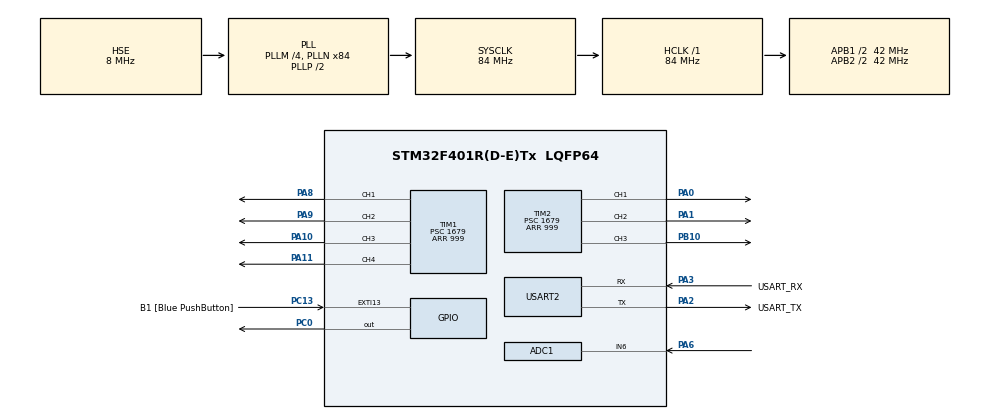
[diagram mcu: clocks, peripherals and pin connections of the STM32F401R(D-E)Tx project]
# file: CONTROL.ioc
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ADC1.Channel-0\#ChannelRegularConversion=ADC_CHANNEL_6
ADC1.NbrOfConversionFlag=1
ADC1.Rank-0\#ChannelRegularConversion=1
ADC1.SamplingTime-0\#ChannelRegularConversion=ADC_SAMPLETIME_3CYCLES
ADC1.master=1
Mcu.Family=STM32F4
Mcu.Name=STM32F401R(D-E)Tx
Mcu.Package=LQFP64
NVIC.PriorityGroup=NVIC_PRIORITYGROUP_0
NVIC.TIM1_BRK_TIM9_IRQn=true\:0\:0\:false\:false\:true\:true
NVIC.TIM1_CC_IRQn=true\:0\:0\:false\:false\:true\:true
NVIC.TIM1_TRG_COM_TIM11_IRQn=true\:0\:0\:false\:false\:true\:true
NVIC.TIM1_UP_TIM10_IRQn=true\:0\:0\:false\:false\:true\:true
NVIC.TIM2_IRQn=true\:0\:0\:false\:false\:true\:true
NVIC.TIM3_IRQn=true\:0\:0\:false\:false\:true\:true
PA0-WKUP.GPIO_Speed=GPIO_SPEED_FREQ_HIGH
PA0-WKUP.Signal=S_TIM2_CH1_ETR
PA1.Signal=S_TIM2_CH2
PA10.GPIO_Speed=GPIO_SPEED_FREQ_VERY_HIGH
PA10.Signal=S_TIM1_CH3
PA11.GPIO_Speed=GPIO_SPEED_FREQ_VERY_HIGH
PA11.Signal=S_TIM1_CH4
PA13.GPIO_Label=TMS
PA13.Mode=Serial_Wire
PA13.Signal=SYS_JTMS-SWDIO
PA14.GPIO_Label=TCK
PA14.Mode=Serial_Wire
PA14.Signal=SYS_JTCK-SWCLK
PA2.GPIO_Label=USART_TX
PA2.GPIO_Mode=GPIO_MODE_AF_PP
PA2.GPIO_PuPd=GPIO_NOPULL
PA2.GPIO_Speed=GPIO_SPEED_FREQ_LOW
PA2.Mode=Asynchronous
PA2.Signal=USART2_TX
PA3.GPIO_Label=USART_RX
PA3.GPIO_Mode=GPIO_MODE_AF_PP
PA3.GPIO_PuPd=GPIO_NOPULL
PA3.GPIO_Speed=GPIO_SPEED_FREQ_LOW
PA3.Mode=Asynchronous
PA3.Signal=USART2_RX
PA6.Signal=ADCx_IN6
PA8.GPIO_Speed=GPIO_SPEED_FREQ_VERY_HIGH
PA8.Signal=S_TIM1_CH1
PA9.GPIO_Speed=GPIO_SPEED_FREQ_VERY_HIGH
PA9.Signal=S_TIM1_CH2
PB10.Signal=S_TIM2_CH3
PB3.GPIO_Label=SWO
PB3.Signal=SYS_JTDO-SWO
PC0.Signal=GPIO_Output
PC13-ANTI_TAMP.GPIO_Label=B1 [Blue PushButton]
PC13-ANTI_TAMP.GPIO_ModeDefaultEXTI=GPIO_MODE_IT_FALLING
PC13-ANTI_TAMP.GPIO_PuPd=GPIO_NOPULL
PC13-ANTI_TAMP.Signal=GPXTI13
PC14-OSC32_IN.Mode=LSE-External-Oscillator
PC14-OSC32_IN.Signal=RCC_OSC32_IN
PC15-OSC32_OUT.Mode=LSE-External-Oscillator
PC15-OSC32_OUT.Signal=RCC_OSC32_OUT
PH0\ -\ OSC_IN.Mode=HSE-External-Clock-Source
PH0\ -\ OSC_IN.Signal=RCC_OSC_IN
PH1\ -\ OSC_OUT.Mode=HSE-External-Clock-Source
PH1\ -\ OSC_OUT.Signal=RCC_OSC_OUT
ProjectManager.HeapSize=0x200
ProjectManager.StackSize=0x400
ProjectManager.TargetToolchain=MDK-ARM V5
RCC.48MHZClocksFreq_Value=24000000
RCC.AHBFreq_Value=84000000
RCC.APB1CLKDivider=RCC_HCLK_DIV2
RCC.APB1Freq_Value=42000000
RCC.APB1TimFreq_Value=84000000
RCC.APB2CLKDivider=RCC_HCLK_DIV2
RCC.APB2Freq_Value=42000000
RCC.APB2TimFreq_Value=84000000
RCC.CortexFreq_Value=84000000
RCC.HCLKFreq_Value=84000000
RCC.HSE_VALUE=8000000
RCC.HSI_VALUE=16000000
RCC.PLLM=8
RCC.PLLN=84
RCC.PLLQ=7
RCC.SYSCLKFreq_VALUE=84000000
RCC.SYSCLKSource=RCC_SYSCLKSOURCE_PLLCLK
RCC.VCOOutputFreq_Value=168000000
SH.ADCx_IN6.0=ADC1_IN6,IN6
SH.S_TIM1_CH1.0=TIM1_CH1,PWM Generation1 CH1
SH.S_TIM1_CH2.0=TIM1_CH2,PWM Generation2 CH2
SH.S_TIM1_CH3.0=TIM1_CH3,PWM Generation3 CH3
SH.S_TIM1_CH4.0=TIM1_CH4,PWM Generation4 CH4
SH.S_TIM2_CH1_ETR.0=TIM2_CH1,PWM Generation1 CH1
SH.S_TIM2_CH2.0=TIM2_CH2,PWM Generation2 CH2
SH.S_TIM2_CH3.0=TIM2_CH3,PWM Generation3 CH3
TIM1.Channel-PWM\ Generation1\ CH1=TIM_CHANNEL_1
TIM1.Channel-PWM\ Generation2\ CH2=TIM_CHANNEL_2
TIM1.Channel-PWM\ Generation3\ CH3=TIM_CHANNEL_3
TIM1.Channel-PWM\ Generation4\ CH4=TIM_CHANNEL_4
TIM1.Period=999
TIM1.Prescaler=1679
TIM2.Channel-PWM\ Generation1\ CH1=TIM_CHANNEL_1
TIM2.Channel-PWM\ Generation2\ CH2=TIM_CHANNEL_2
TIM2.Channel-PWM\ Generation3\ CH3=TIM_CHANNEL_3
TIM2.Period=999
TIM2.Prescaler=1679
TIM3.Period=999
TIM3.Prescaler=8399
USART2.VirtualMode=VM_ASYNC
VP_TIM1_VS_ClockSourceINT.Mode=Internal
VP_TIM2_VS_ClockSourceINT.Mode=Internal
VP_TIM3_VS_ClockSourceINT.Mode=Internal
VP_TIM3_VS_OPM.Mode=OPM_bit
board=NUCLEO-F401RE

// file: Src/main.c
/* USER CODE BEGIN Header */
/**
  ******************************************************************************
  * @file           : main.c
  * @brief          : Main program body
  ******************************************************************************
  ** This notice applies to any and all portions of this file
  * that are not between comment pairs USER CODE BEGIN and
  * USER CODE END. Other portions of this file, whether
  * inserted by the user or by software development tools
  * are owned by their respective copyright owners.
  *
  * COPYRIGHT(c) 2018 STMicroelectronics
  *
  * Redistribution and use in source and binary forms, with or without modification,
  * are permitted provided that the following conditions are met:
  *   1. Redistributions of source code must retain the above copyright notice,
  *      this list of conditions and the following disclaimer.
  *   2. Redistributions in binary form must reproduce the above copyright notice,
  *      this list of conditions and the following disclaimer in the documentation
  *      and/or other materials provided with the distribution.
  *   3. Neither the name of STMicroelectronics nor the names of its contributors
  *      may be used to endorse or promote products derived from this software
  *      without specific prior written permission.
  *
  * THIS SOFTWARE IS PROVIDED BY THE COPYRIGHT HOLDERS AND CONTRIBUTORS "AS IS"
  * AND ANY EXPRESS OR IMPLIED WARRANTIES, INCLUDING, BUT NOT LIMITED TO, THE
  * IMPLIED WARRANTIES OF MERCHANTABILITY AND FITNESS FOR A PARTICULAR PURPOSE ARE
  * DISCLAIMED. IN NO EVENT SHALL THE COPYRIGHT HOLDER OR CONTRIBUTORS BE LIABLE
  * FOR ANY DIRECT, INDIRECT, INCIDENTAL, SPECIAL, EXEMPLARY, OR CONSEQUENTIAL
  * DAMAGES (INCLUDING, BUT NOT LIMITED TO, PROCUREMENT OF SUBSTITUTE GOODS OR
  * SERVICES; LOSS OF USE, DATA, OR PROFITS; OR BUSINESS INTERRUPTION) HOWEVER
  * CAUSED AND ON ANY THEORY OF LIABILITY, WHETHER IN CONTRACT, STRICT LIABILITY,
  * OR TORT (INCLUDING NEGLIGENCE OR OTHERWISE) ARISING IN ANY WAY OUT OF THE USE
  * OF THIS SOFTWARE, EVEN IF ADVISED OF THE POSSIBILITY OF SUCH DAMAGE.
  *
  ******************************************************************************
  */
/* USER CODE END Header */

#include "main.h"

/* USER CODE BEGIN Includes */
#include "servo.h"
#include "motorController.h"
#include <stdlib.h>
//#include "motorController.h"

/* USER CODE END Includes */

ADC_HandleTypeDef hadc1;

TIM_HandleTypeDef htim1;
TIM_HandleTypeDef htim2;
TIM_HandleTypeDef htim3;

UART_HandleTypeDef huart2;

void SystemClock_Config(void);
static void MX_GPIO_Init(void);
static void MX_USART2_UART_Init(void);
static void MX_TIM2_Init(void);
static void MX_ADC1_Init(void);
static void MX_TIM1_Init(void);
static void MX_TIM3_Init(void);

int main(void)
{

  /* MCU Configuration--------------------------------------------------------*/

  /* Reset of all peripherals, Initializes the Flash interface and the Systick. */
  HAL_Init();

  /* Configure the system clock */
  SystemClock_Config();

  /* Initialize all configured peripherals */
  MX_GPIO_Init();
  MX_USART2_UART_Init();
  MX_TIM2_Init();
  MX_ADC1_Init();
  MX_TIM1_Init();
  MX_TIM3_Init();
  /* USER CODE BEGIN 2 */

	// init pwm for servo
	HAL_TIM_PWM_Start( &htim2,TIM_CHANNEL_1 );
	// init pwm for thrasters on timer 1
	HAL_TIM_PWM_Start( &htim1,TIM_CHANNEL_1 );
	HAL_TIM_PWM_Start( &htim1,TIM_CHANNEL_2 );
	HAL_TIM_PWM_Start( &htim1,TIM_CHANNEL_3 );
	HAL_TIM_PWM_Start( &htim1,TIM_CHANNEL_4 );
	// init pwm for thrusters on timer 2
	HAL_TIM_PWM_Start( &htim2,TIM_CHANNEL_2 );
	HAL_TIM_PWM_Start( &htim2,TIM_CHANNEL_3 );

	MotorsInit( &htim1, &htim2 ); // init brushles motors

  /* USER CODE END 2 */

  /* Infinite loop */
  /* USER CODE BEGIN WHILE */
	char Data[32];
  while (1)
  {

				HAL_ADC_Start( &hadc1 );
				HAL_ADC_PollForConversion( &hadc1,100 );
				int power=GetServoAngle( &hadc1 ); //read value from resistor
				power -= 63;
				HAL_ADC_Stop( &hadc1 );
				int size = sprintf((char *)Data,"\r\n%d",power);
				HAL_UART_Transmit(&huart2, Data, size, 1000);

				/*if(__HAL_UART_GET_FLAG(&huart2, UART_FLAG_RXNE))
			{
				HAL_UART_Receive( &huart2, dataAngle,  sizeof(dataAngle), 1000 );

				HAL_UART_Transmit( &huart2, dataAngle, sizeof(dataAngle), 1000 );
				//angle1=SetServoAngle( atoi((char*)dataAngle) ,&hadc1,&htim2 );
				int flag=atoi((char*)dataAngle);

				if(flag==1)
				{
					HAL_GPIO_WritePin(GPIOC, GPIO_PIN_0, GPIO_PIN_SET);
					HAL_Delay(200);
					HAL_GPIO_WritePin(GPIOC, GPIO_PIN_0, GPIO_PIN_RESET);
				}

			}*/

			SetMotorThrust( power,&htim2,2 );
			SetMotorThrust( power,&htim2,3 );

			SetMotorThrust( power,&htim1,1 );
			SetMotorThrust( power,&htim1,2 );
			SetMotorThrust( power,&htim1,3 );
			SetMotorThrust( power,&htim1,4 );

			HAL_Delay( 200 );

    /* USER CODE END WHILE */

  }
}

void SystemClock_Config(void)
{
  RCC_OscInitTypeDef RCC_OscInitStruct = {0};
  RCC_ClkInitTypeDef RCC_ClkInitStruct = {0};

  /**Configure the main internal regulator output voltage
  */
  __HAL_RCC_PWR_CLK_ENABLE();
  __HAL_PWR_VOLTAGESCALING_CONFIG(PWR_REGULATOR_VOLTAGE_SCALE2);
  /**Initializes the CPU, AHB and APB busses clocks
  */
  RCC_OscInitStruct.OscillatorType = RCC_OSCILLATORTYPE_HSE;
  RCC_OscInitStruct.HSEState = RCC_HSE_BYPASS;
  RCC_OscInitStruct.PLL.PLLState = RCC_PLL_ON;
  RCC_OscInitStruct.PLL.PLLSource = RCC_PLLSOURCE_HSE;
  RCC_OscInitStruct.PLL.PLLM = 4;
  RCC_OscInitStruct.PLL.PLLN = 84;
  RCC_OscInitStruct.PLL.PLLP = RCC_PLLP_DIV2;
  RCC_OscInitStruct.PLL.PLLQ = 7;
  if (HAL_RCC_OscConfig(&RCC_OscInitStruct) != HAL_OK)
  {
    Error_Handler();
  }
  /**Initializes the CPU, AHB and APB busses clocks
  */
  RCC_ClkInitStruct.ClockType = RCC_CLOCKTYPE_HCLK|RCC_CLOCKTYPE_SYSCLK
                              |RCC_CLOCKTYPE_PCLK1|RCC_CLOCKTYPE_PCLK2;
  RCC_ClkInitStruct.SYSCLKSource = RCC_SYSCLKSOURCE_PLLCLK;
  RCC_ClkInitStruct.AHBCLKDivider = RCC_SYSCLK_DIV1;
  RCC_ClkInitStruct.APB1CLKDivider = RCC_HCLK_DIV2;
  RCC_ClkInitStruct.APB2CLKDivider = RCC_HCLK_DIV2;

  if (HAL_RCC_ClockConfig(&RCC_ClkInitStruct, FLASH_LATENCY_2) != HAL_OK)
  {
    Error_Handler();
  }
}

static void MX_ADC1_Init(void)
{

  ADC_ChannelConfTypeDef sConfig = {0};

  /**Configure the global features of the ADC (Clock, Resolution, Data Alignment and number of conversion)
  */
  hadc1.Instance = ADC1;
  hadc1.Init.ClockPrescaler = ADC_CLOCK_SYNC_PCLK_DIV2;
  hadc1.Init.Resolution = ADC_RESOLUTION_12B;
  hadc1.Init.ScanConvMode = DISABLE;
  hadc1.Init.ContinuousConvMode = DISABLE;
  hadc1.Init.DiscontinuousConvMode = DISABLE;
  hadc1.Init.ExternalTrigConvEdge = ADC_EXTERNALTRIGCONVEDGE_NONE;
  hadc1.Init.ExternalTrigConv = ADC_SOFTWARE_START;
  hadc1.Init.DataAlign = ADC_DATAALIGN_RIGHT;
  hadc1.Init.NbrOfConversion = 1;
  hadc1.Init.DMAContinuousRequests = DISABLE;
  hadc1.Init.EOCSelection = ADC_EOC_SINGLE_CONV;
  if (HAL_ADC_Init(&hadc1) != HAL_OK)
  {
    Error_Handler();
  }
  /**Configure for the selected ADC regular channel its corresponding rank in the sequencer and its sample time.
  */
  sConfig.Channel = ADC_CHANNEL_6;
  sConfig.Rank = 1;
  sConfig.SamplingTime = ADC_SAMPLETIME_3CYCLES;
  if (HAL_ADC_ConfigChannel(&hadc1, &sConfig) != HAL_OK)
  {
    Error_Handler();
  }

}

static void MX_TIM1_Init(void)
{

  TIM_ClockConfigTypeDef sClockSourceConfig = {0};
  TIM_MasterConfigTypeDef sMasterConfig = {0};
  TIM_OC_InitTypeDef sConfigOC = {0};
  TIM_BreakDeadTimeConfigTypeDef sBreakDeadTimeConfig = {0};

  htim1.Instance = TIM1;
  htim1.Init.Prescaler = 1679;
  htim1.Init.CounterMode = TIM_COUNTERMODE_UP;
  htim1.Init.Period = 999;
  htim1.Init.ClockDivision = TIM_CLOCKDIVISION_DIV1;
  htim1.Init.RepetitionCounter = 0;
  if (HAL_TIM_Base_Init(&htim1) != HAL_OK)
  {
    Error_Handler();
  }
  sClockSourceConfig.ClockSource = TIM_CLOCKSOURCE_INTERNAL;
  if (HAL_TIM_ConfigClockSource(&htim1, &sClockSourceConfig) != HAL_OK)
  {
    Error_Handler();
  }
  if (HAL_TIM_PWM_Init(&htim1) != HAL_OK)
  {
    Error_Handler();
  }
  sMasterConfig.MasterOutputTrigger = TIM_TRGO_RESET;
  sMasterConfig.MasterSlaveMode = TIM_MASTERSLAVEMODE_DISABLE;
  if (HAL_TIMEx_MasterConfigSynchronization(&htim1, &sMasterConfig) != HAL_OK)
  {
    Error_Handler();
  }
  sConfigOC.OCMode = TIM_OCMODE_PWM1;
  sConfigOC.Pulse = 0;
  sConfigOC.OCPolarity = TIM_OCPOLARITY_HIGH;
  sConfigOC.OCNPolarity = TIM_OCNPOLARITY_HIGH;
  sConfigOC.OCFastMode = TIM_OCFAST_DISABLE;
  sConfigOC.OCIdleState = TIM_OCIDLESTATE_RESET;
  sConfigOC.OCNIdleState = TIM_OCNIDLESTATE_RESET;
  if (HAL_TIM_PWM_ConfigChannel(&htim1, &sConfigOC, TIM_CHANNEL_1) != HAL_OK)
  {
    Error_Handler();
  }
  if (HAL_TIM_PWM_ConfigChannel(&htim1, &sConfigOC, TIM_CHANNEL_2) != HAL_OK)
  {
    Error_Handler();
  }
  if (HAL_TIM_PWM_ConfigChannel(&htim1, &sConfigOC, TIM_CHANNEL_3) != HAL_OK)
  {
    Error_Handler();
  }
  if (HAL_TIM_PWM_ConfigChannel(&htim1, &sConfigOC, TIM_CHANNEL_4) != HAL_OK)
  {
    Error_Handler();
  }
  sBreakDeadTimeConfig.OffStateRunMode = TIM_OSSR_DISABLE;
  sBreakDeadTimeConfig.OffStateIDLEMode = TIM_OSSI_DISABLE;
  sBreakDeadTimeConfig.LockLevel = TIM_LOCKLEVEL_OFF;
  sBreakDeadTimeConfig.DeadTime = 0;
  sBreakDeadTimeConfig.BreakState = TIM_BREAK_DISABLE;
  sBreakDeadTimeConfig.BreakPolarity = TIM_BREAKPOLARITY_HIGH;
  sBreakDeadTimeConfig.AutomaticOutput = TIM_AUTOMATICOUTPUT_DISABLE;
  if (HAL_TIMEx_ConfigBreakDeadTime(&htim1, &sBreakDeadTimeConfig) != HAL_OK)
  {
    Error_Handler();
  }
  HAL_TIM_MspPostInit(&htim1);

}

static void MX_TIM2_Init(void)
{

  TIM_ClockConfigTypeDef sClockSourceConfig = {0};
  TIM_MasterConfigTypeDef sMasterConfig = {0};
  TIM_OC_InitTypeDef sConfigOC = {0};

  htim2.Instance = TIM2;
  htim2.Init.Prescaler = 1679;
  htim2.Init.CounterMode = TIM_COUNTERMODE_UP;
  htim2.Init.Period = 999;
  htim2.Init.ClockDivision = TIM_CLOCKDIVISION_DIV1;
  if (HAL_TIM_Base_Init(&htim2) != HAL_OK)
  {
    Error_Handler();
  }
  sClockSourceConfig.ClockSource = TIM_CLOCKSOURCE_INTERNAL;
  if (HAL_TIM_ConfigClockSource(&htim2, &sClockSourceConfig) != HAL_OK)
  {
    Error_Handler();
  }
  if (HAL_TIM_PWM_Init(&htim2) != HAL_OK)
  {
    Error_Handler();
  }
  sMasterConfig.MasterOutputTrigger = TIM_TRGO_RESET;
  sMasterConfig.MasterSlaveMode = TIM_MASTERSLAVEMODE_DISABLE;
  if (HAL_TIMEx_MasterConfigSynchronization(&htim2, &sMasterConfig) != HAL_OK)
  {
    Error_Handler();
  }
  sConfigOC.OCMode = TIM_OCMODE_PWM1;
  sConfigOC.Pulse = 0;
  sConfigOC.OCPolarity = TIM_OCPOLARITY_HIGH;
  sConfigOC.OCFastMode = TIM_OCFAST_DISABLE;
  if (HAL_TIM_PWM_ConfigChannel(&htim2, &sConfigOC, TIM_CHANNEL_1) != HAL_OK)
  {
    Error_Handler();
  }
  if (HAL_TIM_PWM_ConfigChannel(&htim2, &sConfigOC, TIM_CHANNEL_2) != HAL_OK)
  {
    Error_Handler();
  }
  if (HAL_TIM_PWM_ConfigChannel(&htim2, &sConfigOC, TIM_CHANNEL_3) != HAL_OK)
  {
    Error_Handler();
  }
  HAL_TIM_MspPostInit(&htim2);

}

static void MX_TIM3_Init(void)
{

  TIM_ClockConfigTypeDef sClockSourceConfig = {0};
  TIM_MasterConfigTypeDef sMasterConfig = {0};
  TIM_OC_InitTypeDef sConfigOC = {0};

  htim3.Instance = TIM3;
  htim3.Init.Prescaler = 8399;
  htim3.Init.CounterMode = TIM_COUNTERMODE_UP;
  htim3.Init.Period = 999;
  htim3.Init.ClockDivision = TIM_CLOCKDIVISION_DIV1;
  if (HAL_TIM_Base_Init(&htim3) != HAL_OK)
  {
    Error_Handler();
  }
  sClockSourceConfig.ClockSource = TIM_CLOCKSOURCE_INTERNAL;
  if (HAL_TIM_ConfigClockSource(&htim3, &sClockSourceConfig) != HAL_OK)
  {
    Error_Handler();
  }
  if (HAL_TIM_PWM_Init(&htim3) != HAL_OK)
  {
    Error_Handler();
  }
  if (HAL_TIM_OnePulse_Init(&htim3, TIM_OPMODE_SINGLE) != HAL_OK)
  {
    Error_Handler();
  }
  sMasterConfig.MasterOutputTrigger = TIM_TRGO_RESET;
  sMasterConfig.MasterSlaveMode = TIM_MASTERSLAVEMODE_DISABLE;
  if (HAL_TIMEx_MasterConfigSynchronization(&htim3, &sMasterConfig) != HAL_OK)
  {
    Error_Handler();
  }
  sConfigOC.OCMode = TIM_OCMODE_PWM1;
  sConfigOC.Pulse = 0;
  sConfigOC.OCPolarity = TIM_OCPOLARITY_HIGH;
  sConfigOC.OCFastMode = TIM_OCFAST_DISABLE;
  if (HAL_TIM_PWM_ConfigChannel(&htim3, &sConfigOC, TIM_CHANNEL_1) != HAL_OK)
  {
    Error_Handler();
  }
  HAL_TIM_MspPostInit(&htim3);

}

static void MX_USART2_UART_Init(void)
{

  huart2.Instance = USART2;
  huart2.Init.BaudRate = 115200;
  huart2.Init.WordLength = UART_WORDLENGTH_8B;
  huart2.Init.StopBits = UART_STOPBITS_1;
  huart2.Init.Parity = UART_PARITY_NONE;
  huart2.Init.Mode = UART_MODE_TX_RX;
  huart2.Init.HwFlowCtl = UART_HWCONTROL_NONE;
  huart2.Init.OverSampling = UART_OVERSAMPLING_16;
  if (HAL_UART_Init(&huart2) != HAL_OK)
  {
    Error_Handler();
  }

}

static void MX_GPIO_Init(void)
{
  GPIO_InitTypeDef GPIO_InitStruct = {0};

  /* GPIO Ports Clock Enable */
  __HAL_RCC_GPIOC_CLK_ENABLE();
  __HAL_RCC_GPIOH_CLK_ENABLE();
  __HAL_RCC_GPIOA_CLK_ENABLE();
  __HAL_RCC_GPIOB_CLK_ENABLE();

  /*Configure GPIO pin Output Level */
  HAL_GPIO_WritePin(GPIOC, GPIO_PIN_0, GPIO_PIN_RESET);

  /*Configure GPIO pin Output Level */
  HAL_GPIO_WritePin(LD2_GPIO_Port, LD2_Pin, GPIO_PIN_RESET);

  /*Configure GPIO pin : B1_Pin */
  GPIO_InitStruct.Pin = B1_Pin;
  GPIO_InitStruct.Mode = GPIO_MODE_IT_FALLING;
  GPIO_InitStruct.Pull = GPIO_NOPULL;
  HAL_GPIO_Init(B1_GPIO_Port, &GPIO_InitStruct);

  /*Configure GPIO pin : PC0 */
  GPIO_InitStruct.Pin = GPIO_PIN_0;
  GPIO_InitStruct.Mode = GPIO_MODE_OUTPUT_PP;
  GPIO_InitStruct.Pull = GPIO_NOPULL;
  GPIO_InitStruct.Speed = GPIO_SPEED_FREQ_LOW;
  HAL_GPIO_Init(GPIOC, &GPIO_InitStruct);

  /*Configure GPIO pin : LD2_Pin */
  GPIO_InitStruct.Pin = LD2_Pin;
  GPIO_InitStruct.Mode = GPIO_MODE_OUTPUT_PP;
  GPIO_InitStruct.Pull = GPIO_NOPULL;
  GPIO_InitStruct.Speed = GPIO_SPEED_FREQ_LOW;
  HAL_GPIO_Init(LD2_GPIO_Port, &GPIO_InitStruct);

}

void Error_Handler(void)
{
}

/************************ (C) COPYRIGHT STMicroelectronics *****END OF FILE****/
